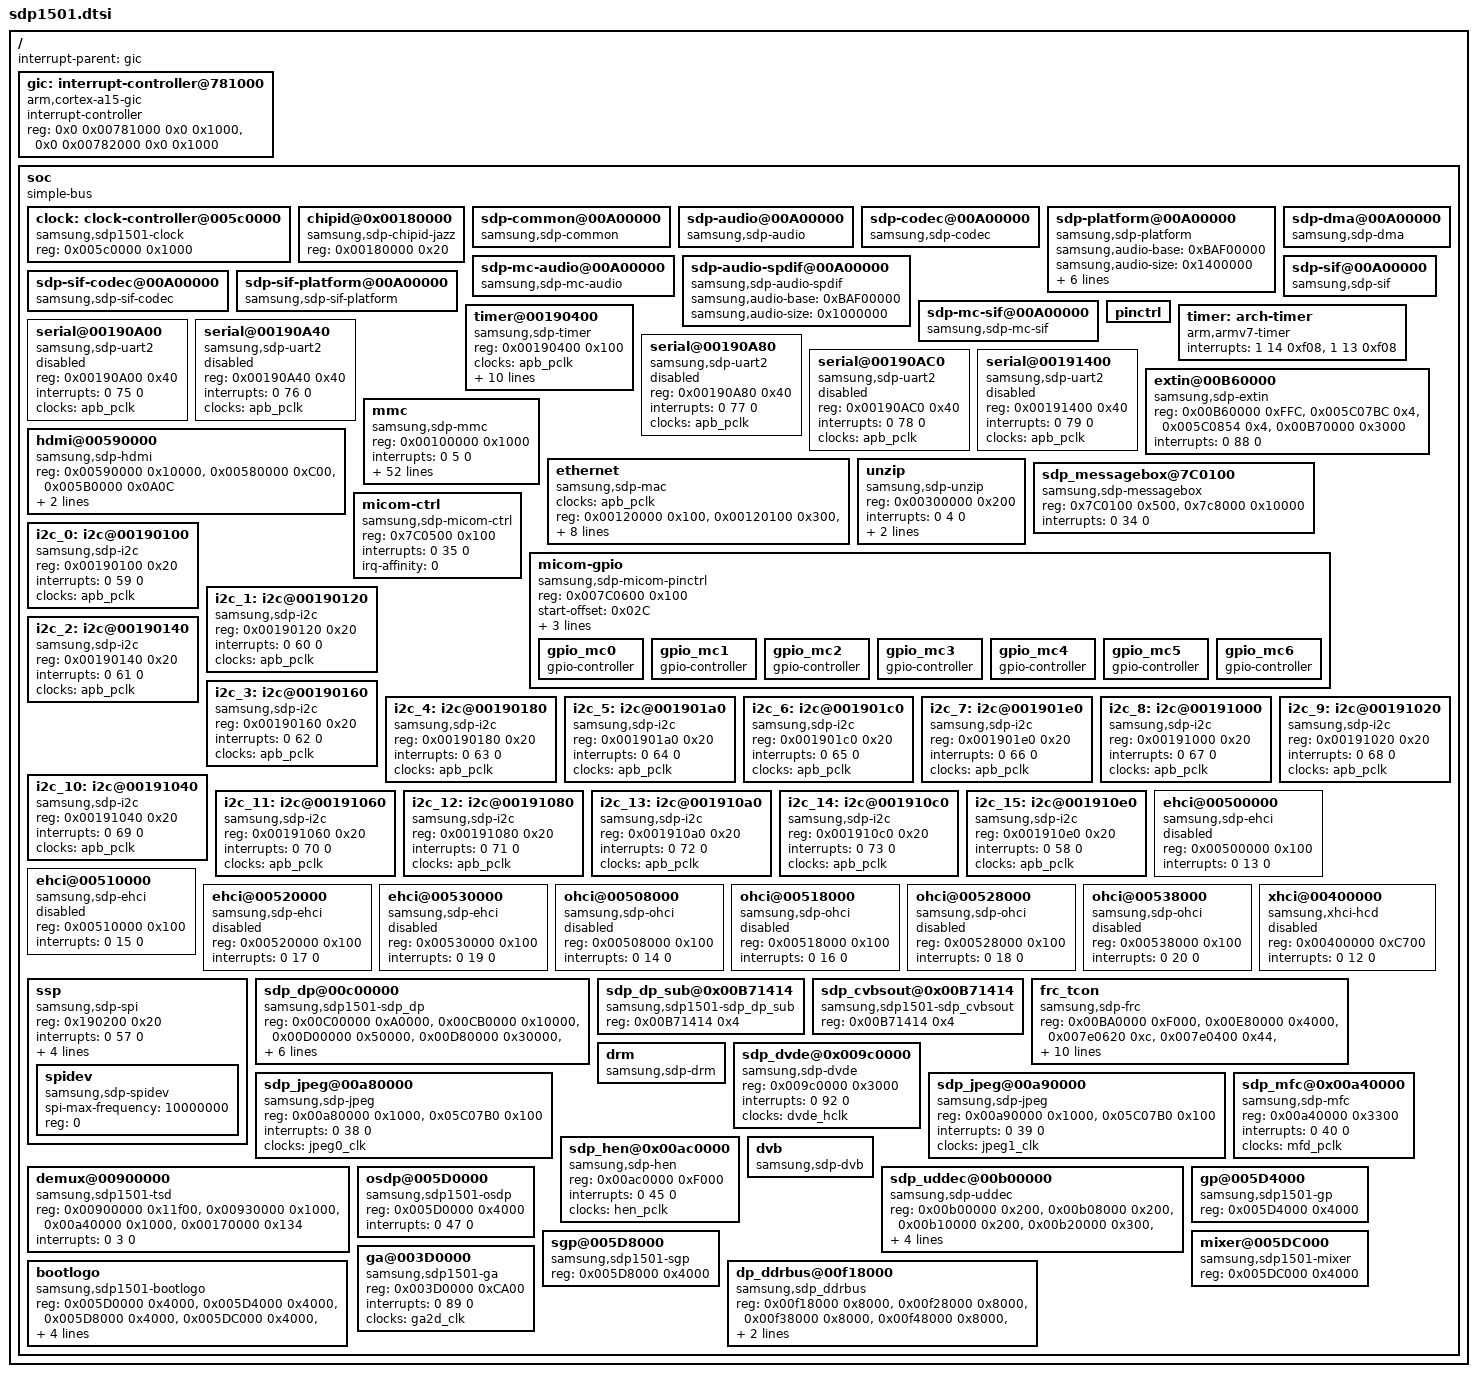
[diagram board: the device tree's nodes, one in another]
/*
 * Copyright (C) 2015 Samsung Electronics Co.Ltd
 *
 * This program is free software; you can redistribute it and/or modify
 * it under the terms of the GNU General Public License version 2 as
 * published by the Free Software Foundation.
 */

#include <dt-bindings/interrupt-controller/arm-gic.h>

#include "sdp.dtsi"
#include "sdp1501-clocks.dtsi"
#include "sdp1501-pinctrl.dtsi"

/ {

	interrupt-parent = <&gic>;

	gic: interrupt-controller@781000 {
		compatible = "arm,cortex-a15-gic";
		interrupt-controller;
		#interrupt-cells = <3>;
		reg = <0x0 0x00781000 0x0 0x1000>, <0x0 0x00782000 0x0 0x1000>;
	};

	soc: soc {
		compatible = "simple-bus";
		#address-cells = <1>;
		#size-cells = <1>;	
		ranges = <0x0 0x0 0x0 0xffffffff>;

		clock:clock-controller@005c0000 {
			compatible = "samsung,sdp1501-clock";
			reg = <0x005c0000 0x1000>;
			#clock-cells = <1>;
		};

		chipid@0x00180000 {
			compatible = "samsung,sdp-chipid-jazz";
			reg = <0x00180000 0x20>;
		};

		sdp-common@00A00000{
			compatible = "samsung,sdp-common";
		};

		sdp-audio@00A00000 {
			compatible = "samsung,sdp-audio";
		};

		sdp-codec@00A00000  {
			compatible = "samsung,sdp-codec";
		};

		sdp-platform@00A00000  {
			compatible = "samsung,sdp-platform";
			samsung,audio-base = <0xBAF00000>;
			samsung,audio-size = <0x1400000>;
			samsung,hw-reg-base = <0x00A00000>;
			samsung,hw-reg-size = <0x12000>;
			samsung,hw-clkreg-base = <0x005C0000>;
			samsung,hw-clkreg-size = <0x1000>;
			samsung,audio-aio-irq = <0x50>;
			samsung,audio-ae-irq = <0x51>;
		};

		sdp-dma@00A00000  {
			compatible = "samsung,sdp-dma";
		};


		sdp-mc-audio@00A00000  {
			compatible = "samsung,sdp-mc-audio";
		};


		sdp-audio-spdif@00A00000  {
			compatible = "samsung,sdp-audio-spdif";
			samsung,audio-base = <0xBAF00000>;
			samsung,audio-size = <0x1000000>;
		};


		sdp-sif@00A00000  {
			compatible = "samsung,sdp-sif";
		};

		/*ALSA SIF*/
		sdp-sif-codec@00A00000  {
			compatible = "samsung,sdp-sif-codec";
		};

		sdp-sif-platform@00A00000  {
			compatible = "samsung,sdp-sif-platform";
		};


		sdp-mc-sif@00A00000  {
			compatible = "samsung,sdp-mc-sif";
		};

		pinctrl{
			status = "okay";
		};

		timer: arch-timer {
			//always-on;
			compatible = "arm,armv7-timer";
			interrupts = <1 14 0xf08>,
					<1 13 0xf08>;
		};

		timer@00190400 {
			compatible = "samsung,sdp-timer";
			reg = <0x00190400 0x100>;
			clocks = <&apb_pclk>;
			clock-names = "apb_pclk";
			int_stretch = <0xf>;
			int_level;
			one-shot;
			nr_timers = <8>;
			interrupts = <0 80 0>, <0 81 0>, <0 82 0>, <0 83 0>, <0 84 0>, <0 85 0>, <0 86 0>, <0 87 0>;
			clocksource_id = <0>;
			clockevent_id = <1>;
			localtimer_ids = <2>, <3>, <4>, <5>;
			clkevt_local_rating = <500>;
		};

		serial@00190A00 {
			compatible = "samsung,sdp-uart2";
			reg = <0x00190A00 0x40>;
			interrupts = <0 75 0>;
			clocks = <&apb_pclk>;
			clock-names = "apb_pclk";
			status = "disabled";
		};

		serial@00190A40 {
			compatible = "samsung,sdp-uart2";
			reg = <0x00190A40 0x40>;
			interrupts = <0 76 0>;
			clocks = <&apb_pclk>;
			clock-names = "apb_pclk";
			//irq-affinity = <2>;
			status = "disabled";
		};

		serial@00190A80 {
			compatible = "samsung,sdp-uart2";
			reg = <0x00190A80 0x40>;
			interrupts = <0 77 0>;
			clocks = <&apb_pclk>;
			clock-names = "apb_pclk";
			//irq-affinity = <2>;
			status = "disabled";
		};

		serial@00190AC0 {
			compatible = "samsung,sdp-uart2";
			reg = <0x00190AC0 0x40>;
			interrupts = <0 78 0>;
			clocks = <&apb_pclk>;
			clock-names = "apb_pclk";
			//irq-affinity = <2>;
			status = "disabled";
		};

		serial@00191400 {
			compatible = "samsung,sdp-uart2";
			reg = <0x00191400 0x40>;
			interrupts = <0 79 0>;
			clocks = <&apb_pclk>;
			clock-names = "apb_pclk";
			//irq-affinity = <2>;
			status = "disabled";
		};

		extin@00B60000 {
			compatible = "samsung,sdp-extin";
			reg = <0x00B60000 0xFFC>, <0x005C07BC 0x4>, <0x005C0854 0x4>, <0x00B70000 0x3000>;
			reg-names = "avd-reg", "reg-mp0_sw_rst", "reg-mux_sel6", "afe-reg";
			interrupts = <0 88 0>;
		};

		hdmi@00590000 {
				 compatible = "samsung,sdp-hdmi";
				 reg = <0x00590000 0x10000>, <0x00580000 0xC00>, <0x005B0000 0x0A0C>;
				 reg-names = "hdmi-reg", "hdmi-edid-reg", "hdmi-common-reg";
				 interrupts = <0 90 0>, <0 91 0>, <0 27 0>, <0 26 0>, <0 29 0>, <0 30 0>;

		};

		mmc {
			compatible = "samsung,sdp-mmc";
			reg = <0x00100000 0x1000>;
			interrupts = <0 5 0>;
			clocks = <&emmc_clk>;
			clock-names = "emmc_clk";
			fifo-depth = <0x40>;
			min-max-clock = <400000 200000000>;

			initregs = <0x001000A8 0x00C7800F 0x00040000>;/* low speed delay */

			tuning_set_size = <2>;

			tuning_sam_hs200_default = <0x001000A8 0x0000000F 0x00000000>, <0x00100110 0x0 0x0>;
			tuning_drv_hs200_default = <0x001000A8 0x00C78000 0x00058000>, <0x00100110 0x0 0x0>;
			tuning_sam =
						<0x001000A8 0xCF 0x01>, <0x00100110 0x3 0x0>,
						<0x001000A8 0xCF 0x41>, <0x00100110 0x3 0x0>,
						<0x001000A8 0xCF 0x02>, <0x00100110 0x3 0x0>,
						<0x001000A8 0xCF 0x42>, <0x00100110 0x3 0x0>,
						<0x001000A8 0xCF 0x03>, <0x00100110 0x3 0x0>,
						<0x001000A8 0xCF 0x43>, <0x00100110 0x3 0x0>,
						<0x001000A8 0xCF 0x04>, <0x00100110 0x3 0x0>,
						<0x001000A8 0xCF 0x44>, <0x00100110 0x3 0x0>,
						<0x001000A8 0xCF 0x05>, <0x00100110 0x3 0x0>,
						<0x001000A8 0xCF 0x45>, <0x00100110 0x3 0x0>,
						<0x001000A8 0xCF 0x06>, <0x00100110 0x3 0x0>,
						<0x001000A8 0xCF 0x46>, <0x00100110 0x3 0x0>,
						<0x001000A8 0xCF 0x07>, <0x00100110 0x3 0x0>,
						<0x001000A8 0xCF 0x47>, <0x00100110 0x3 0x0>,
						<0x001000A8 0xCF 0x08>, <0x00100110 0x3 0x0>,
						<0x001000A8 0xCF 0x48>, <0x00100110 0x3 0x0>;

			tuning_sam_hs400_default = <0x001000A8 0x000000CF 0x00000003>, <0x00100188 0x000003FF 0x000000C0>;/* default read dqs delay(45step) */
			tuning_drv_hs400_default = <0x001000A8 0x00C78000 0x00068000>, <0x00100110 0x0 0x0>;
			tuning_sam_hs400 =
						<0x001000A8 0xCF 0x01>, <0x00100110 0x3 0x0>,
						<0x001000A8 0xCF 0x41>, <0x00100110 0x3 0x0>,
						<0x001000A8 0xCF 0x81>, <0x00100110 0x3 0x0>,
						<0x001000A8 0xCF 0x02>, <0x00100110 0x3 0x0>,
						<0x001000A8 0xCF 0x42>, <0x00100110 0x3 0x0>,
						<0x001000A8 0xCF 0x82>, <0x00100110 0x3 0x0>,
						<0x001000A8 0xCF 0x03>, <0x00100110 0x3 0x0>,
						<0x001000A8 0xCF 0x43>, <0x00100110 0x3 0x0>,
						<0x001000A8 0xCF 0x83>, <0x00100110 0x3 0x0>,
						<0x001000A8 0xCF 0x04>, <0x00100110 0x3 0x0>,
						<0x001000A8 0xCF 0x44>, <0x00100110 0x3 0x0>,
						<0x001000A8 0xCF 0x84>, <0x00100110 0x3 0x0>;

			bus-width = <0x8>;
	//		force-pio-mode;
			hw-reset;

			/* Host Caps */
			non-removable;
	//		bus-width-test;
			highspeed;
	//		sdr104;
	//		ddr50;
	//		hs200;
	//		hs200-tuning;
			hs400;
		};


		ethernet {
			compatible = "samsung,sdp-mac";
			clocks = <&apb_pclk>;
			clock-names = "emac_clk";
			reg = <0x00120000 0x100>,
				<0x00120100 0x300>,
				<0x00120700 0x100>,
				<0x00120800 0x100>,
				<0x00121000 0x100>;
			interrupts = <0 7 0>;
			pad_ctrl_reg = <0x00130000 0x1 0x1>;/* select SRAM for MAC */
			phy_sel_reg = <0x005C1080  0x20000000 0x20000000>;		/* select RGMII register */
			bus_width = <64>;
			phy_mask = <0>;
			napi_weight = <32>;
		};

		unzip {
		        compatible = "samsung,sdp-unzip";
		        reg = <0x00300000 0x200>;
		        interrupts = < 0 4 0 >;
			irq-affinity = <0>;
		        clocks = <&apb_pclk>;
		        clock-names = "apb_pclk";
		        //status = "disabled";
		};

		/* Micom */
		sdp_messagebox@7C0100 {
			compatible = "samsung,sdp-messagebox";
			reg = <0x7C0100 0x500>, <0x7c8000 0x10000>;
			interrupts = <0 34 0>;
		};

		micom-ctrl {
			compatible = "samsung,sdp-micom-ctrl";
			reg = <0x7C0500 0x100>;
			interrupts = <0 35 0>;
			irq-affinity = <0>;
		};

		micom-gpio {
			compatible = "samsung,sdp-micom-pinctrl";
			reg = <0x007C0600 0x100>;
			start-offset = <0x02C>;
			nr-banks = <7>;
			model-sel = <1>;

			index-base = <400>;

			//Micom GPIOs
			gpio_mc0 {
				gpio-controller;
				#gpio-cells = <3>;
			};
			gpio_mc1 {
				gpio-controller;
				#gpio-cells = <3>;
			};
			gpio_mc2 {
				gpio-controller;
				#gpio-cells = <3>;
			};
			gpio_mc3 {
				gpio-controller;
				#gpio-cells = <3>;
			};
			gpio_mc4 {
				gpio-controller;
				#gpio-cells = <3>;
			};
			gpio_mc5 {
				gpio-controller;
				#gpio-cells = <3>;
			};
			gpio_mc6 {
				gpio-controller;
				#gpio-cells = <3>;
			};
		};

	/* Hawk-M Old property */
		
		i2c_0: i2c@00190100 {
			#address-cells = <1>;
			#size-cells = <0>;
			compatible = "samsung,sdp-i2c";
			reg = <0x00190100 0x20>;
			interrupts = <0 59 0>;
			clocks = <&apb_pclk>;
			clock-names = "rstn_i2c";
		};

		i2c_1: i2c@00190120 {
			#address-cells = <1>;
			#size-cells = <0>;
			compatible = "samsung,sdp-i2c";
			reg = <0x00190120 0x20>;
			interrupts = <0 60 0>;
			clocks = <&apb_pclk>;
			clock-names = "rstn_i2c";
		};

		i2c_2: i2c@00190140 {
			#address-cells = <1>;
			#size-cells = <0>;
			compatible = "samsung,sdp-i2c";
			reg = <0x00190140 0x20>;
			interrupts = <0 61 0>;
			clocks = <&apb_pclk>;
			clock-names = "rstn_i2c";
		};

		i2c_3: i2c@00190160 {
			#address-cells = <1>;
			#size-cells = <0>;
			compatible = "samsung,sdp-i2c";
			reg = <0x00190160 0x20>;
			interrupts = <0 62 0>;
			clocks = <&apb_pclk>;
			clock-names = "rstn_i2c";
		};

		i2c_4: i2c@00190180 {
			#address-cells = <1>;
			#size-cells = <0>;
			compatible = "samsung,sdp-i2c";
			reg = <0x00190180 0x20>;
			interrupts = <0 63 0>;
			clocks = <&apb_pclk>;
			clock-names = "rstn_i2c";
		};

		i2c_5: i2c@001901a0 {
			#address-cells = <1>;
			#size-cells = <0>;
			compatible = "samsung,sdp-i2c";
			reg = <0x001901a0 0x20>;
			interrupts = <0 64 0>;
			clocks = <&apb_pclk>;
			clock-names = "rstn_i2c";
		};

		i2c_6: i2c@001901c0 {
			#address-cells = <1>;
			#size-cells = <0>;
			compatible = "samsung,sdp-i2c";
			reg = <0x001901c0 0x20>;
			interrupts = <0 65 0>;
			clocks = <&apb_pclk>;
			clock-names = "rstn_i2c";
		};

		i2c_7: i2c@001901e0 {
			#address-cells = <1>;
			#size-cells = <0>;
			compatible = "samsung,sdp-i2c";
			reg = <0x001901e0 0x20>;
			interrupts = <0 66 0>;
			clocks = <&apb_pclk>;
			clock-names = "rstn_i2c";
		};

		i2c_8: i2c@00191000 {
			#address-cells = <1>;
			#size-cells = <0>;
			compatible = "samsung,sdp-i2c";
			reg = <0x00191000 0x20>;
			interrupts = <0 67 0>;
			clocks = <&apb_pclk>;
			clock-names = "rstn_i2c";
		};

		i2c_9: i2c@00191020 {
			#address-cells = <1>;
			#size-cells = <0>;
			compatible = "samsung,sdp-i2c";
			reg = <0x00191020 0x20>;
			interrupts = <0 68 0>;
			clocks = <&apb_pclk>;
			clock-names = "rstn_i2c";
		};

		i2c_10: i2c@00191040 {
			#address-cells = <1>;
			#size-cells = <0>;
			compatible = "samsung,sdp-i2c";
			reg = <0x00191040 0x20>;
			interrupts = <0 69 0>;
			clocks = <&apb_pclk>;
			clock-names = "rstn_i2c";
		};

		i2c_11: i2c@00191060 {
			#address-cells = <1>;
			#size-cells = <0>;
			compatible = "samsung,sdp-i2c";
			reg = <0x00191060 0x20>;
			interrupts = <0 70 0>;
			clocks = <&apb_pclk>;
			clock-names = "rstn_i2c";
		};

		i2c_12: i2c@00191080 {
			#address-cells = <1>;
			#size-cells = <0>;
			compatible = "samsung,sdp-i2c";
			reg = <0x00191080 0x20>;
			interrupts = <0 71 0>;
			clocks = <&apb_pclk>;
			clock-names = "rstn_i2c";
		};
		
		i2c_13: i2c@001910a0 {
			#address-cells = <1>;
			#size-cells = <0>;
			compatible = "samsung,sdp-i2c";
			reg = <0x001910a0 0x20>;
			interrupts = <0 72 0>;
			clocks = <&apb_pclk>;
			clock-names = "rstn_i2c";
		};

		i2c_14: i2c@001910c0 {
			#address-cells = <1>;
			#size-cells = <0>;
			compatible = "samsung,sdp-i2c";
			reg = <0x001910c0 0x20>;
			interrupts = <0 73 0>;
			clocks = <&apb_pclk>;
			clock-names = "rstn_i2c";
		};

		i2c_15: i2c@001910e0 {
			#address-cells = <1>;
			#size-cells = <0>;
			compatible = "samsung,sdp-i2c";
			reg = <0x001910e0 0x20>;
			interrupts = <0 58 0>;
			clocks = <&apb_pclk>;
			clock-names = "rstn_i2c";
		};
	/*
		i2c_HS: i2c@00190000 {
			#address-cells = <1>;
			#size-cells = <0>;
			compatible = "samsung,sdp-i2c-hs";
			reg = <0x00190000 0x100>;
			interrupts = <0 39 0>;
			clocks = <&apb_pclk>;
			clock-names = "rstn_i2c";
		};
	*/
		ehci@00500000 {
			compatible = "samsung,sdp-ehci", "usb-ehci";
			reg = <0x00500000 0x100>;
			interrupts = <0 13 0>;
			status = "disabled";
		};

		ehci@00510000 {
			compatible = "samsung,sdp-ehci", "usb-ehci";
			reg = <0x00510000 0x100>;
			interrupts = <0 15 0>;
			status = "disabled";
		};

		ehci@00520000 {
			compatible = "samsung,sdp-ehci", "usb-ehci";
			reg = <0x00520000 0x100>;
			interrupts = <0 17 0>;
			status = "disabled";
		};

		ehci@00530000 {
			compatible = "samsung,sdp-ehci", "usb-ehci";
			reg = <0x00530000 0x100>;
			interrupts = <0 19 0>;
			status = "disabled";
		};

		ohci@00508000 {
			compatible = "samsung,sdp-ohci", "usb-ohci";
			reg = <0x00508000 0x100>;
			interrupts = <0 14 0>;
			status = "disabled";
		};

		ohci@00518000 {
			compatible = "samsung,sdp-ohci", "usb-ohci";
			reg = <0x00518000 0x100>;
			interrupts = <0 16 0>;
			status = "disabled";
		};

		ohci@00528000 {
			compatible = "samsung,sdp-ohci", "usb-ohci";
			reg = <0x00528000 0x100>;
			interrupts = <0 18 0>;
			status = "disabled";
		};

		ohci@00538000 {
			compatible = "samsung,sdp-ohci", "usb-ohci";
			reg = <0x00538000 0x100>;
			interrupts = <0 20 0>;
			status = "disabled";
		};


		xhci@00400000 {
			compatible = "samsung,xhci-hcd", "usb-xhci";
			reg = <0x00400000 0xC700>;
			interrupts = <0 12 0>;
			status = "disabled";
		};


		ssp {
			status = "okay";
			compatible = "samsung,sdp-spi";
			reg = <0x190200 0x20>;
			interrupts = <0 57 0>;
			clocks = <&apb_pclk>;
			clock-names = "apb_pclk";

			#address-cells = <1>;
			#size-cells = <0>;

			/* TODO: pad ctrl reg setting... */
			initregs =	<0x005C1040 0x00080000 0x00080000>;/* PAD SPI_SEL */
			max-clock-limit = <25000000>;
			bus-num = <0x0>;

			//cs-gpios = <&gpio10 5 0>;/* o_SMC_ADDR[1] port (P10.5) Ctrl reg */

			spidev {
				#address-cells = <1>;
				#size-cells = <1>;
				compatible = "samsung,sdp-spidev";
				spi-max-frequency = <10000000>;
				reg = <0>;
			};
	/*
			flash: w25x40@0 {
				#address-cells = <1>;
				#size-cells = <1>;
				compatible = "winbond,w25x40";
				spi-max-frequency = <10000000>;
				reg = <0>;

				partition@0 {
					label = "ucode";
					reg = <0x0 0x80000>;
				};
			};
	*/
		};

		sdp_dp@00c00000 {
			compatible = "samsung,sdp1501-sdp_dp";
			reg =	<0x00C00000	0xA0000>,	/*TOP_DP_SCL*/
			<0x00CB0000	0x10000>,	/*TOP_DP_SCL2*/
			<0x00D00000	0x50000>,	/*TOP_DP_NRFC1*/
			<0x00D80000	0x30000>,	/*TOP_DP_NRFC2*/
			<0x00DC0000	0x20000>,	/*TOP_DP_NRFC3*/
			<0x00980000	0x38000>,	/*TOP_DP_VE*/
			<0x00B90000	0x10000>,	/*TOP_DP_TFC*/
			<0x00B80000	0x10000>,	/*TOP_DP_ROT*/
			<0x005C0008	0x4>,		/*TOP_VID_PLL_PMS*/
			<0x005C001C	0x4>,		/*TOP_VX1_PLL_PMS*/
			<0x005C00F8	0x4>;		/*TOP_VID_CLK_MUX_SEL*/


			interrupts              = <0 94 0>;
			samsung,dp_ttx_out      = <0 0x7EA00000 0x40000>;        /* 256KB */

	/*
			clocks = <&disp_pclk_nr>,  <&disp_pclk_dcar>,  <&disp_pclk_ipc>,  <&disp_pclk_ucar>,  <&dp_scl_sub_clk>,   <&dp_scl_pclk>;
			clock-names = "disp_pclk_nr", "disp_pclk_dcar", "disp_pclk_ipc", "disp_pclk_ucar", "dp_scl_sub_clk", "dp_scl_pclk";
	*/
		};
		sdp_dp_sub@0x00B71414 {
			compatible = "samsung,sdp1501-sdp_dp_sub";
			reg = <0x00B71414 0x4>;		/* AFE - OUT-PATH */
		};
		sdp_cvbsout@0x00B71414 {
			compatible = "samsung,sdp1501-sdp_cvbsout";
			reg = <0x00B71414 0x4>;		/* AFE - OUT-PATH */
		};

		frc_tcon {
			compatible = "samsung,sdp-frc";
			reg = <0x00BA0000 0xF000>, <0x00E80000 0x4000>, <0x007e0620 0xc>, <0x007e0400 0x44>, <0x007e0480 0x44>, <0x005c1300 0x100>, <0x005c07c0 0xc>, <0x007e0290 0x8>;
			reg-names = "frc-reg", "tcon-reg","tcon-conf", "msgbox-rx", "msgbox-tx", "top-conf", "clk-conf", "dmic-spi";
			interrupts = <0 36 0>;
			dev_id = <1>;
			output= <120>;
			region_init_size = <236>;
			region_init = <
				0x3000 0x0000DCA0 0xFFFF
				0x3004 0x0000DCC4 0xFFFF
				0x3008 0x0000DCE8 0xFFFF
				0x300C 0x0000DD0C 0xFFFF
				0x3010 0x0000DD30 0xFFFF
				0x3014 0x0000DD54 0xFFFF
				0x3018 0x0000DD78 0xFFFF
				0x301C 0x0000DD9C 0xFFFF
				0x3020 0x0000BE94 0xFFFF
				0x3024 0x0000BEB8 0xFFFF
				0x3028 0x0000BEDC 0xFFFF
				0x302C 0x0000BF00 0xFFFF
				0x3030 0x0000BE94 0xFFFF
				0x3034 0x0000BE94 0xFFFF
				0x3038 0x0000BE94 0xFFFF
				0x303C 0x0000BE94 0xFFFF
				0x3040 0x0000BE94 0xFFFF
				0x3044 0x0000BE94 0xFFFF
				0x3048 0x0000BE94 0xFFFF
				0x304C 0x0000BE94 0xFFFF
				0x3050 0x0000BE94 0xFFFF
				0x3054 0x0000BE94 0xFFFF
				0x3058 0x0000BE94 0xFFFF
				0x305C 0x0000BE94 0xFFFF
				0x3060 0x0000BE94 0xFFFF
				0x3064 0x0000BE99 0xFFFF
				0x3068 0x0000BE9E 0xFFFF
				0x306C 0x0000BEA3 0xFFFF
				0x3070 0x0000BEA8 0xFFFF
				0x3074 0x0000BEAA 0xFFFF
				0x3078 0x0000BEAC 0xFFFF
				0x307C 0x0000BEAE 0xFFFF
				0x3080 0x0000BEB0 0xFFFF
				0x3084 0x0000BEB2 0xFFFF
				0x3088 0x0000BEB4 0xFFFF
				0x308C 0x0000BEB6 0xFFFF
				0x3090 0x0000BEB8 0xFFFF
				0x3094 0x0000BEBA 0xFFFF
				0x3098 0x0000BEBC 0xFFFF
				0x309C 0x0000BEBE 0xFFFF
				0x30A0 0x0000BEC0 0xFFFF
				0x30A4 0x0000BEC2 0xFFFF
				0x30A8 0x0000BEC4 0xFFFF
				0x30AC 0x0000BEC6 0xFFFF
				0x30B0 0x0000BEC8 0xFFFF
				0x30B4 0x0000BECA 0xFFFF
				0x30B8 0x0000BECC 0xFFFF
				0x30BC 0x0000BECE 0xFFFF
				0x30C0 0x0000BED0 0xFFFF
				0x30C4 0x0000BED2 0xFFFF
				0x30C8 0x0000BED4 0xFFFF
				0x30CC 0x0000BED6 0xFFFF
				0x30D0 0x0000BED8 0xFFFF
				0x30D4 0x0000BEDA 0xFFFF
				0x30D8 0x0000BEDC 0xFFFF
				0x30DC 0x0000BEDE 0xFFFF
				0x30E0 0x0000BEE0 0xFFFF
				0x30E4 0x0000BEE2 0xFFFF
				0x30E8 0x0000BEE4 0xFFFF
				0x30EC 0x0000BEE9 0xFFFF
				0x30F0 0x0000BEEE 0xFFFF
				0x30F4 0x0000BEF3 0xFFFF
				0x30F8 0x0000BEFC 0xFFFF
				0x30FC 0x0000BF10 0xFFFF
				0x3100 0x0000BF2A 0xFFFF
				0x3104 0x0000BF41 0xFFFF
				0x3108 0x0000BF58 0xFFFF
				0x310C 0x0000BF6F 0xFFFF
				0x3110 0x0000BF86 0xFFFF
				0x3114 0x0000BF9D 0xFFFF
				0x3118 0x0000BFB4 0xFFFF
				0x311C 0x0000BEFC 0xFFFF
				0x3120 0x0000BF10 0xFFFF
				0x3124 0x0000BF2A 0xFFFF
				0x3128 0x0000BF41 0xFFFF
				0x312C 0x0000BF58 0xFFFF
				0x3130 0x0000BF6F 0xFFFF
				0x3134 0x0000BF86 0xFFFF
				0x3138 0x0000BF9D 0xFFFF
				0x313C 0x0000BFB4 0xFFFF
				0x3140 0x0000BFCB 0xFFFF
				0x3144 0x0000BFCC 0xFFFF
				0x3148 0x0000BFCE 0xFFFF
				0x314C 0x0000BFCF 0xFFFF
				0x3150 0x0000BFD0 0xFFFF
				0x3154 0x0000BFD1 0xFFFF
				0x3158 0x0000BFD2 0xFFFF
				0x315C 0x0000BFD3 0xFFFF
				0x3160 0x0000BFD4 0xFFFF
				0x3164 0x0000BFD5 0xFFFF
				0x3168 0x0000BFD6 0xFFFF
				0x316C 0x0000BFDF 0xFFFF
				0x3170 0x0000BFE8 0xFFFF
				0x3174 0x0000BFF1 0xFFFF
				0x4000 0x00009AE8 0xFFFF
				0x4004 0x00009AE9 0xFFFF
				0x4008 0x00009AEA 0xFFFF
				0x400C 0x00009AEB 0xFFFF
				0x4010 0x00009AEC 0xFFFF
				0x4014 0x00009AED 0xFFFF
				0x4018 0x00009AEE 0xFFFF
				0x401C 0x00009AEF 0xFFFF
				0x4020 0x00009AF0 0xFFFF
				0x4024 0x00009AF1 0xFFFF
				0x4028 0x00009AF2 0xFFFF
				0x402C 0x00009AF3 0xFFFF
				0x4030 0x00009AF4 0xFFFF
				0x4034 0x00009AF5 0xFFFF
				0x4038 0x00009AF6 0xFFFF
				0x403C 0x00009AF7 0xFFFF
				0x4040 0x00009AF8 0xFFFF
				0x4044 0x00009AF9 0xFFFF
				0x4048 0x00009AFA 0xFFFF
				0x404C 0x00009AFB 0xFFFF
				0x4050 0x00009AFC 0xFFFF
				0x4054 0x00009AFD 0xFFFF
				0x4058 0x00009AFE 0xFFFF
				0x405C 0x00009AFF 0xFFFF
				0x4060 0x00009B00 0xFFFF
				0x4064 0x00009B01 0xFFFF
				0x4068 0x00009B02 0xFFFF
				0x406C 0x00009B03 0xFFFF
				0x4070 0x00009B04 0xFFFF
				0x4074 0x00009B05 0xFFFF
				0x4078 0x00009B06 0xFFFF
				0x407C 0x00009B07 0xFFFF
				0x8E00 0x0000DCA0 0xFFFF
				0x8E04 0x0000DCC4 0xFFFF
				0x8E08 0x0000DCE8 0xFFFF
				0x8E0C 0x0000DD0C 0xFFFF
				0x8E10 0x0000DD30 0xFFFF
				0x8E14 0x0000DD54 0xFFFF
				0x8E18 0x0000DD78 0xFFFF
				0x8E1C 0x0000DD9C 0xFFFF
				0x8E20 0x0000BE94 0xFFFF
				0x8E24 0x0000BEB8 0xFFFF
				0x8E28 0x0000BEDC 0xFFFF
				0x8E2C 0x0000BF00 0xFFFF
				0x8E30 0x0000BEA8 0xFFFF
				0x8E34 0x0000BEAA 0xFFFF
				0x8E38 0x0000BEAC 0xFFFF
				0x8E3C 0x0000BEAE 0xFFFF
				0x8E40 0x0000BEB0 0xFFFF
				0x8E44 0x0000BEB2 0xFFFF
				0x8E48 0x0000BEB4 0xFFFF
				0x8E4C 0x0000BEB6 0xFFFF
				0x8E50 0x0000BEB8 0xFFFF
				0x8E54 0x0000BEBA 0xFFFF
				0x8E58 0x0000BEBC 0xFFFF
				0x8E5C 0x0000BEBE 0xFFFF
				0x8E60 0x0000BEC0 0xFFFF
				0x8E64 0x0000BEC2 0xFFFF
				0x8E68 0x0000BEC4 0xFFFF
				0x8E6C 0x0000BEC6 0xFFFF
				0x8E70 0x0000BEC8 0xFFFF
				0x8E74 0x0000BECA 0xFFFF
				0x8E78 0x0000BECC 0xFFFF
				0x8E7C 0x0000BECE 0xFFFF
				0x8E80 0x0000BED0 0xFFFF
				0x8E84 0x0000BED2 0xFFFF
				0x8E88 0x0000BED4 0xFFFF
				0x8E8C 0x0000BED6 0xFFFF
				0x8E90 0x0000BED8 0xFFFF
				0x8E94 0x0000BEDA 0xFFFF
				0x8E98 0x0000BEDC 0xFFFF
				0x8E9C 0x0000BEDE 0xFFFF
				0x8EA0 0x0000BEE0 0xFFFF
				0x8EA4 0x0000BEE2 0xFFFF
				0x8EA8 0x0000BEE4 0xFFFF
				0x8EAC 0x0000BEE9 0xFFFF
				0x8EB0 0x0000BEEE 0xFFFF
				0x8EB4 0x0000BEF3 0xFFFF
				0x8EB8 0x0000BFD2 0xFFFF
				0x8EBC 0x0000BFD3 0xFFFF
				0x8EC0 0x0000BFD4 0xFFFF
				0x8EC4 0x0000BFD5 0xFFFF
				0xA000 0x00008AC2 0xFFFF
				0xA004 0x00008AE6 0xFFFF
				0xA008 0x00008B0A 0xFFFF
				0xA00C 0x00008B2E 0xFFFF
				0xA010 0x00008B52 0xFFFF
				0xA014 0x00008B76 0xFFFF
				0xA018 0x00008B9A 0xFFFF
				0xA01C 0x00008BBE 0xFFFF
				0xA020 0x0000DDC0 0xFFFF
				0xA024 0x0000DDE4 0xFFFF
				0xA028 0x0000DE08 0xFFFF
				0xA02C 0x0000DE2C 0xFFFF
				0xA030 0x0000DE50 0xFFFF
				0xA034 0x0000DE74 0xFFFF
				0xA038 0x0000DE98 0xFFFF
				0xA03C 0x0000DEBC 0xFFFF
				0xA040 0x00008AC2 0xFFFF
				0xA044 0x00008AE6 0xFFFF
				0xA048 0x00008B0A 0xFFFF
				0xA04C 0x00008B2E 0xFFFF
				0xA050 0x00008B52 0xFFFF
				0xA054 0x00008B76 0xFFFF
				0xA058 0x00008B9A 0xFFFF
				0xA05C 0x00008BBE 0xFFFF
				0xA060 0x0000DDC0 0xFFFF
				0xA064 0x0000DDE4 0xFFFF
				0xA068 0x0000DE08 0xFFFF
				0xA06C 0x0000DE2C 0xFFFF
				0xA070 0x0000DE50 0xFFFF
				0xA074 0x0000DE74 0xFFFF
				0xA078 0x0000DE98 0xFFFF
				0xA07C 0x0000DEBC 0xFFFF
				0xA080 0x0000BE94 0xFFFF
				0xA084 0x0000BEB8 0xFFFF
				0xA088 0x0000BEDC 0xFFFF
				0xA08C 0x0000BF00 0xFFFF
				0xA090 0x0000BE94 0xFFFF
				0xA094 0x0000BEB8 0xFFFF
				0xA098 0x0000BEDC 0xFFFF
				0xA09C 0x0000BF00 0xFFFF
				0xA42C 0x00008BE2 0xFFFF
				0xA430 0x00008C06 0xFFFF
				0xA434 0x00008C2A 0xFFFF
				0xA438 0x00008C4E 0xFFFF
				0xA43C 0x0000DEE0 0xFFFF
				0xA440 0x0000DF04 0xFFFF
				0xA444 0x0000DF28 0xFFFF
				0xA448 0x0000DF4C 0xFFFF
				0xA44C 0x00008BE2 0xFFFF
				0xA450 0x00008C06 0xFFFF
				0xA454 0x00008C2A 0xFFFF
				0xA458 0x00008C4E 0xFFFF
				0xA45C 0x0000DEE0 0xFFFF
				0xA460 0x0000DF04 0xFFFF
				0xA464 0x0000DF28 0xFFFF
				0xA468 0x0000DF4C 0xFFFF
				0x317C 0x00000000 0xFFFF
				0x3180 0x00000000 0xFFFF
				0x8F88 0x00000000 0xFFFF
				0x8F8C 0x00000000 0xFFFF
				>;
			active_init = <
				0xc 0x00100000 0x00100000
			>;
			tcon_initdata = <
				/* AGING_EN */
				0xc8 0x10 0x30
			>;
		};

		drm {
				compatible = "samsung,sdp-drm";
		};

		sdp_dvde@0x009c0000 {
					compatible = "samsung,sdp-dvde";
					reg = <0x009c0000 0x3000>;
					interrupts = <0 92 0>;
					
					clocks = <&dvde_hclk>;
					clock-names = "dvde_hclk";
					
		};

		 sdp_jpeg@00a80000 {
	                compatible = "samsung,sdp-jpeg";
	                reg = <0x00a80000 0x1000>, <0x05C07B0 0x100>;
	                interrupts = <0 38 0>;
			clocks = <&jpeg0_clk>;
			clock-names = "jpeg0_clk";
	        };
	        
	        sdp_jpeg@00a90000 {
	                compatible = "samsung,sdp-jpeg";
	                reg = <0x00a90000 0x1000>, <0x05C07B0 0x100>;
	                interrupts = <0 39 0>;
			clocks = <&jpeg1_clk>;
			clock-names = "jpeg1_clk";
	        };


		sdp_mfc@0x00a40000 {
					compatible = "samsung,sdp-mfc";
					reg = <0x00a40000 0x3300>;
					interrupts = <0 40 0>;
					clocks = <&mfd_pclk>;
					clock-names = "mfd_pclk";
			};

		sdp_hen@0x00ac0000 {
					compatible = "samsung,sdp-hen";
					reg = <0x00ac0000 0xF000>;
					interrupts = <0 45 0>;
					clocks = <&hen_pclk>;
					clock-names = "hen_pclk";
			};

		dvb {
				compatible = "samsung,sdp-dvb";
		};

		demux@00900000 {
			compatible = "samsung,sdp1501-tsd";
			reg = <0x00900000 0x11f00>, <0x00930000 0x1000>, <0x00a40000 0x1000>, <0x00170000 0x134>;
			reg-names = "tsd", "se", "mfd", "ci";
			interrupts = <0 3 0>;
		};

		sdp_uddec@00b00000 {
			compatible = "samsung,sdp-uddec";
			reg = <0x00b00000 0x200>, <0x00b08000 0x200>, <0x00b10000 0x200>, <0x00b20000 0x300>, <0x00b28000 0x300>, <0x00b40000 0x3000>, <0x00a40000 0x3300>;
			reg-names = "g1dec0", "g1dec1", "g1dec2", "g2dec0", "vocrc", "hevcuhd", "mfc";
			interrupts = <0 108 0>, <0 76 0>, <0 77 0>, <0 78 0>, <0 79 0>;
			};

		osdp@005D0000 {
			compatible = "samsung,sdp1501-osdp";
			reg =   <0x005D0000 0x4000>;
			interrupts = <0 47 0>;
		};

		gp@005D4000 {
			compatible = "samsung,sdp1501-gp";
			reg = <0x005D4000 0x4000>;
		};

		sgp@005D8000 {
			compatible = "samsung,sdp1501-sgp";
			reg = <0x005D8000 0x4000>;
		};

		mixer@005DC000 {
			compatible = "samsung,sdp1501-mixer";
			reg =  <0x005DC000 0x4000>;
		};

		ga@003D0000 {
			compatible = "samsung,sdp1501-ga";
			reg = <0x003D0000 0xCA00>;
			interrupts = <0 89 0>;
			clocks = <&ga2d_clk>;
			clock-names = "ga2d_clk";
		};

		bootlogo {                                                 
		    compatible = "samsung,sdp1501-bootlogo";               
		    reg =   <0x005D0000 0x4000>,
			<0x005D4000 0x4000>,
			<0x005D8000 0x4000>,
			<0x005DC000 0x4000>,
			<0x003D0000 0x4000>,
			<0x00980000 0xD000>,
			<0x00C00000 0x20000>;
		    interrupts = <0 47 0>,
			       <0 89 0>;
			clocks = <&ga2d_clk>;
			clock-names = "ga2d_clk";
		};

		dp_ddrbus@00f18000 {
			compatible = "samsung,sdp_ddrbus";
			reg = <0x00f18000 0x8000>,   /* MEMS_A */
				<0x00f28000 0x8000>,   /* MEMS_B */
				<0x00f38000 0x8000>,   /* MEMS_C */
				<0x00f48000 0x8000>,   /* MEMS_D */
				<0x00f58000 0x8000>,   /* MEMS_E */
				<0x007b0000 0x8000>,   /* BUS_MON_CPU */
				<0x00a20000 0x8000>;   /* BUS_MON_AUD */
			reg-names = "MEMS_A","MEMS_B","MEMS_C","MEMS_D","MEMS_E",
				"BUS_MON_CPU","BUS_MON_AUD";
		};
	};
};
